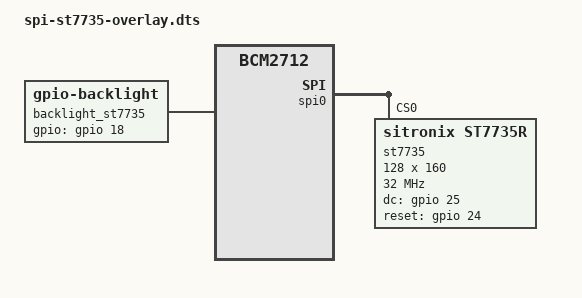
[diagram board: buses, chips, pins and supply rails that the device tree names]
// Raspberry Pi 5 - ST7735 SPI Display Overlays
// Device Tree Overlays for ST7735 based displays
// Copyright (C) 2025 The Android Open Source Project

/dts-v1/;
/plugin/;

// ============================================================================
// ST7735 1.8" TFT Display (128x160)
// ============================================================================
/ {
    compatible = "brcm,bcm2712";
    
    fragment@0 {
        target = <&spi0>;
        __overlay__ {
            status = "okay";
            #address-cells = <1>;
            #size-cells = <0>;
            
            st7735: st7735@0 {
                compatible = "sitronix,st7735r";
                reg = <0>;
                spi-max-frequency = <32000000>;
                
                dc-gpios = <&gpio 25 0>;
                reset-gpios = <&gpio 24 0>;
                
                width = <128>;
                height = <160>;
                buswidth = <8>;
                fps = <30>;
                bgr;
            };
        };
    };
    
    fragment@1 {
        target-path = "/";
        __overlay__ {
            backlight_st7735: backlight {
                compatible = "gpio-backlight";
                gpios = <&gpio 18 0>;
                default-on;
            };
        };
    };
};
